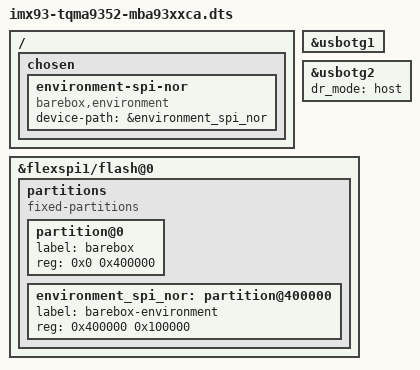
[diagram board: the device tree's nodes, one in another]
// SPDX-License-Identifier: (GPL-2.0-or-later OR MIT)
// SPDX-License-Identifier: (GPL-2.0-or-later OR MIT)

#include <arm64/freescale/imx93-tqma9352-mba93xxca.dts>
#include "imx93.dtsi"

/{
	chosen {
		environment-spi-nor {
			compatible = "barebox,environment";
			device-path = &environment_spi_nor;
		};
	};
};

&usbotg1 {
	status = "okay";
};

&usbotg2 {
	status = "okay";
	dr_mode = "host";
};

&{flexspi1/flash@0} {
	partitions {
		compatible = "fixed-partitions";
		#address-cells = <1>;
		#size-cells = <1>;

		partition@0 {
			label = "barebox";
			reg = <0x0 0x400000>;
		};

		environment_spi_nor: partition@400000 {
			label = "barebox-environment";
			reg = <0x400000 0x100000>;
		};
	};
};
